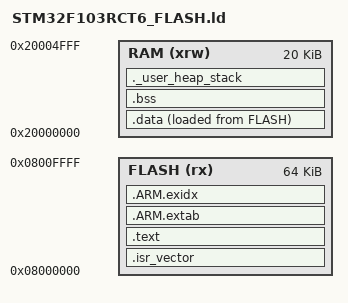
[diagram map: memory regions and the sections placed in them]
ENTRY(Reset_Handler)

_estack = ORIGIN(RAM) + LENGTH(RAM);

_Min_Heap_Size = 0x0000;
_Min_Stack_Size = 0x1000;

MEMORY
{
    FLASH (rx) : ORIGIN = 0x08000000, LENGTH = 64K
    RAM   (xrw) : ORIGIN = 0x20000000, LENGTH = 20K
}

SECTIONS
{
    .isr_vector :
    {
        . = ALIGN(4);
        KEEP(*(.isr_vector))
        . = ALIGN(4);
    } > FLASH

    .text :
    {
        . = ALIGN(4);

        *(.text)
        *(.text*)

        *(.rodata)
        *(.rodata*)

        . = ALIGN(4);
        _etext = .;
    } > FLASH

        .ARM.extab :
    {
        . = ALIGN(4);
        *(.ARM.extab* .gnu.linkonce.armextab.*)
        . = ALIGN(4);
    } > FLASH

    .ARM.exidx :
    {
        . = ALIGN(4);
        __exidx_start = .;
        *(.ARM.exidx* .gnu.linkonce.armexidx.*)
        __exidx_end = .;
        . = ALIGN(4);
    } > FLASH

    _sidata = LOADADDR(.data);

    .data :
    {
        . = ALIGN(4);

        _sdata = .;

        *(.data)
        *(.data*)

        . = ALIGN(4);

        _edata = .;
    } > RAM AT > FLASH

    .bss :
    {
        . = ALIGN(4);

        _sbss = .;

        *(.bss)
        *(.bss*)
        *(COMMON)

        . = ALIGN(4);

        _ebss = .;
    } > RAM

    ._user_heap_stack :
    {
        . = ALIGN(8);

        PROVIDE(end = .);
        PROVIDE(_end = .);

        . = . + _Min_Heap_Size;
        . = . + _Min_Stack_Size;

        . = ALIGN(8);
    } > RAM

    /DISCARD/ :
    {
        *(.note.GNU-stack)
        *(.gnu_debuglink)
    }
}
